AUTOSAR XML (schema 4-0-3)
package /ComponentTypes
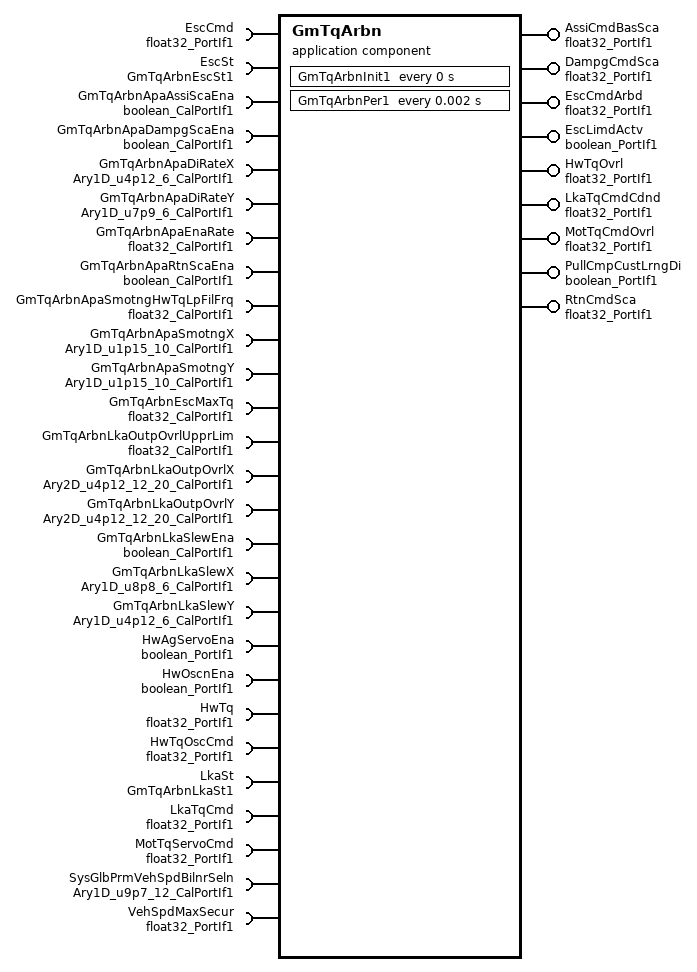
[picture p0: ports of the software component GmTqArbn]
  application sw component type GmTqArbn
    9 x provide port:
      AssiCmdBasSca: nonqueued-sender-com-spec{data-element=Val, init-value=0}, provided-interface=float32_PortIf1
      DampgCmdSca: nonqueued-sender-com-spec{data-element=Val, init-value=0}, provided-interface=float32_PortIf1
      EscCmdArbd: nonqueued-sender-com-spec{data-element=Val, init-value=0}, provided-interface=float32_PortIf1
      EscLimdActv: nonqueued-sender-com-spec{data-element=Logl, init-value=0}, provided-interface=boolean_PortIf1
      HwTqOvrl: nonqueued-sender-com-spec{data-element=Val, init-value=0}, provided-interface=float32_PortIf1
      LkaTqCmdCdnd: nonqueued-sender-com-spec{data-element=Val, init-value=0}, provided-interface=float32_PortIf1
      MotTqCmdOvrl: nonqueued-sender-com-spec{data-element=Val, init-value=0}, provided-interface=float32_PortIf1
      PullCmpCustLrngDi: nonqueued-sender-com-spec{data-element=Logl, init-value=0}, provided-interface=boolean_PortIf1
      RtnCmdSca: nonqueued-sender-com-spec{data-element=Val, init-value=0}, provided-interface=float32_PortIf1
    27 x require port:
      EscCmd: nonqueued-receiver-com-spec{data-element=Val, filter=data-filter-type=ALWAYS, init-value=0}, required-interface=float32_PortIf1
      EscSt: nonqueued-receiver-com-spec{data-element=Val, filter=data-filter-type=ALWAYS, init-value=0}, required-interface=GmTqArbnEscSt1
      GmTqArbnApaAssiScaEna: parameter-require-com-spec{init-value=1, parameter=Logl}, required-interface=boolean_CalPortIf1
      GmTqArbnApaDampgScaEna: parameter-require-com-spec{init-value=1, parameter=Logl}, required-interface=boolean_CalPortIf1
      GmTqArbnApaDiRateX: parameter-require-com-spec{init-value=[0, 4096, 8192, 12288, 16384, 28672], parameter=Ary1D}, required-interface=Ary1D_u4p12_6_CalPortIf1
      GmTqArbnApaDiRateY: parameter-require-com-spec{init-value=[154, 205, 256, 512, 1024, 2560], parameter=Ary1D}, required-interface=Ary1D_u7p9_6_CalPortIf1
      GmTqArbnApaEnaRate: parameter-require-com-spec{init-value=0.5, parameter=Val}, required-interface=float32_CalPortIf1
      GmTqArbnApaRtnScaEna: parameter-require-com-spec{init-value=1, parameter=Logl}, required-interface=boolean_CalPortIf1
      GmTqArbnApaSmotngHwTqLpFilFrq: parameter-require-com-spec{init-value=3, parameter=Val}, required-interface=float32_CalPortIf1
      GmTqArbnApaSmotngX: parameter-require-com-spec{init-value=[0, 3277, 6554, 9830, 13107, 19661, 22938, 26214, 29491, 32768], parameter=Ary1D}, required-interface=Ary1D_u1p15_10_CalPortIf1
      GmTqArbnApaSmotngY: parameter-require-com-spec{init-value=[0, 786, 3113, 6750, 11305, 21463, 26018, 29655, 31982, 32768], parameter=Ary1D}, required-interface=Ary1D_u1p15_10_CalPortIf1
      GmTqArbnEscMaxTq: parameter-require-com-spec{init-value=3, parameter=Val}, required-interface=float32_CalPortIf1
      GmTqArbnLkaOutpOvrlUpprLim: parameter-require-com-spec{init-value=0.15, parameter=Val}, required-interface=float32_CalPortIf1
      GmTqArbnLkaOutpOvrlX: parameter-require-com-spec{init-value=12 x [0, 0, 27, 55, 82, 109, 136, 164, 191, 218, 246, 273, 300, 327, 355, 382, 437, 5541, 12628, 16441], parameter=Ary2D}, required-interface=Ary2D_u4p12_12_20_CalPortIf1
      GmTqArbnLkaOutpOvrlY: parameter-require-com-spec{init-value=12 x 20 x 0, parameter=Ary2D}, required-interface=Ary2D_u4p12_12_20_CalPortIf1
      GmTqArbnLkaSlewEna: parameter-require-com-spec{init-value=0, parameter=Logl}, required-interface=boolean_CalPortIf1
      GmTqArbnLkaSlewX: parameter-require-com-spec{init-value=[2560, 10240, 17920, 25600, 33280, 46080], parameter=Ary1D}, required-interface=Ary1D_u8p8_6_CalPortIf1
      GmTqArbnLkaSlewY: parameter-require-com-spec{init-value=6 x 12288, parameter=Ary1D}, required-interface=Ary1D_u4p12_6_CalPortIf1
      HwAgServoEna: nonqueued-receiver-com-spec{data-element=Logl, filter=data-filter-type=ALWAYS, init-value=0}, required-interface=boolean_PortIf1
      HwOscnEna: nonqueued-receiver-com-spec{data-element=Logl, filter=data-filter-type=ALWAYS, init-value=0}, required-interface=boolean_PortIf1
      HwTq: nonqueued-receiver-com-spec{data-element=Val, filter=data-filter-type=ALWAYS, init-value=0}, required-interface=float32_PortIf1
      HwTqOscCmd: nonqueued-receiver-com-spec{data-element=Val, filter=data-filter-type=ALWAYS, init-value=0}, required-interface=float32_PortIf1
      LkaSt: nonqueued-receiver-com-spec{data-element=Val, filter=data-filter-type=ALWAYS, init-value=0}, required-interface=GmTqArbnLkaSt1
      LkaTqCmd: nonqueued-receiver-com-spec{data-element=Val, filter=data-filter-type=ALWAYS, init-value=0}, required-interface=float32_PortIf1
      MotTqServoCmd: nonqueued-receiver-com-spec{data-element=Val, filter=data-filter-type=ALWAYS, init-value=0}, required-interface=float32_PortIf1
      SysGlbPrmVehSpdBilnrSeln: parameter-require-com-spec{init-value=[0, 640, 1920, 3840, 7680, 10240, 12800, 15360, 19200, 23040, 25600, 28160], parameter=Ary1D}, required-interface=Ary1D_u9p7_12_CalPortIf1
      VehSpdMaxSecur: nonqueued-receiver-com-spec{data-element=Val, filter=data-filter-type=ALWAYS, init-value=0}, required-interface=float32_PortIf1
    behavior GmTqArbn_InternalBehavior
      ar-typed-per-instance-memorys:
        9 x data, all with sw-calibration-access=READ-ONLY:
          ActPosnServoCmd: type=float32
          APASmotngHwTqLpFil: type=FilLpRec1
          DesLkaTqCmdRateLim: type=float32
          dGmTqArbnDesLkaTqCmd: type=float32
          dGmTqArbnEscTqCmd: type=float32
          dGmTqArbnLkaOutpTqReq: type=float32
          dGmTqArbnLkaTqCmd: type=float32
          dGmTqArbnPosnServoSmotngLowrLim: type=float32
          PosnServoSmotngEnaRateLim: type=float32
      timing event GmTqArbn_InitEvent: start-on-event=GmTqArbnInit1, period=0
      timing event TMT_GmTqArbnPer1: start-on-event=GmTqArbnPer1, period=0.002
      runnable GmTqArbnInit1
      runnable GmTqArbnPer1
        data-receive-point-by-arguments:
          10 x access:
            REC_EscCmd_Val: accessed-variable=EscCmd.Val
            REC_EscSt_Val: accessed-variable=EscSt.Val
            REC_HwOscnEna_Logl: accessed-variable=HwOscnEna.Logl
            REC_HwTq_Val: accessed-variable=HwTq.Val
            REC_HwTqOscCmd_Val: accessed-variable=HwTqOscCmd.Val
            REC_LkaSt_Val: accessed-variable=LkaSt.Val
            REC_LkaTqCmd_Val: accessed-variable=LkaTqCmd.Val
            REC_MtrTqServoCmd_Val: accessed-variable=MotTqServoCmd.Val
            REC_MtrTqServoSmotngEna_Logl: accessed-variable=HwAgServoEna.Logl
            REC_VehSpdMaxSecur_Val: accessed-variable=VehSpdMaxSecur.Val
        data-send-points:
          9 x access:
            SEND_AssiCmdBasSca_Val: accessed-variable=AssiCmdBasSca.Val
            SEND_DampgCmdSca_Val: accessed-variable=DampgCmdSca.Val
            SEND_EscCmdArbd_Val: accessed-variable=EscCmdArbd.Val
            SEND_EscLimdActv_Logl: accessed-variable=EscLimdActv.Logl
            SEND_HwTqOvrl_Val: accessed-variable=HwTqOvrl.Val
            SEND_LkaTqCmdCdnd_Val: accessed-variable=LkaTqCmdCdnd.Val
            SEND_MotTqCmdOvrl_Val: accessed-variable=MotTqCmdOvrl.Val
            SEND_PullCmpCustLrngDi_Logl: accessed-variable=PullCmpCustLrngDi.Logl
            SEND_RtnCmdSca_Val: accessed-variable=RtnCmdSca.Val
  swc implementation GmTqArbn_Implementation: behavior=GmTqArbn_InternalBehavior
    code-descriptors:
      code Default: artifact-descriptors=autosar-engineering-object={short-label=Default, category=SWSRC}
